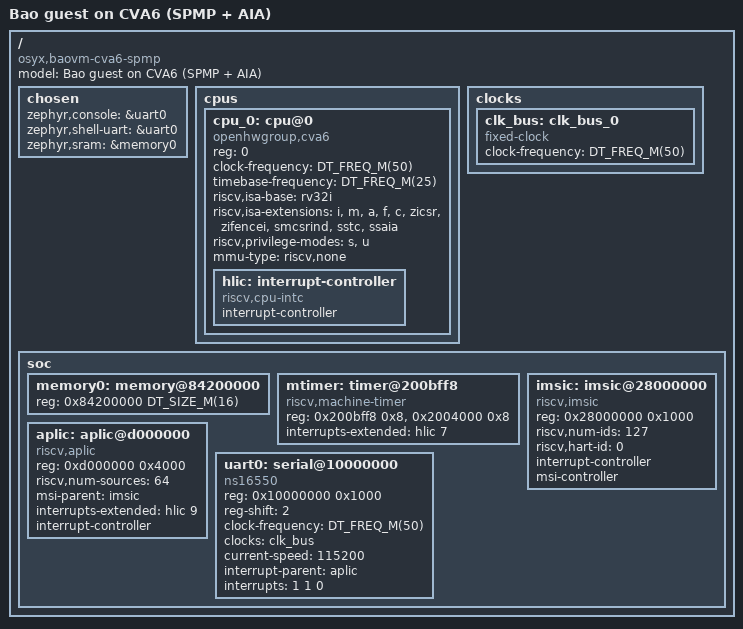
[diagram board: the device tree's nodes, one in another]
/*
 * SPDX-License-Identifier: Apache-2.0
 *
 * Bao guest on a CVA6-based MCU-class platform with SPMP and AIA.
 *
 * Addresses and IRQ numbers below match the cva6-spmp-guide Bao guest
 * configuration (cva6/bao_configs/cva6-spmp-dual-bm.c):
 *
 *   - VM memory region: 0x84200000, 16 MiB;
 *   - UART (NS16550): 0x10000000, 4 KiB, APLIC source 1;
 *   - AIA: APLIC at 0xd000000, IMSIC at 0x28000000;
 *   - IPC shared memory: 0x8A000000, 16 KiB, APLIC source 3
 *     (declared in the app.overlay, not here).
 */
/dts-v1/;

#include <freq.h>
#include <mem.h>

/ {
	model = "Bao guest on CVA6 (SPMP + AIA)";
	compatible = "osyx,baovm-cva6-spmp";

	#address-cells = <1>;
	#size-cells = <1>;

	chosen {
		zephyr,console = &uart0;
		zephyr,shell-uart = &uart0;
		zephyr,sram = &memory0;
	};

	cpus {
		#address-cells = <1>;
		#size-cells = <0>;

		cpu_0: cpu@0 {
			device_type = "cpu";
			compatible = "openhwgroup,cva6", "riscv";
			reg = <0>;
			clock-frequency = <DT_FREQ_M(50)>;
			timebase-frequency = <DT_FREQ_M(25)>;
			riscv,isa-base = "rv32i";
			riscv,isa-extensions = "i", "m", "a", "f", "c",
					       "zicsr", "zifencei",
					       "smcsrind", "sstc", "ssaia";
			riscv,privilege-modes = "s", "u";
			mmu-type = "riscv,none";
			status = "okay";

			hlic: interrupt-controller {
				#interrupt-cells = <1>;
				interrupt-controller;
				compatible = "riscv,cpu-intc";
				status = "okay";
			};
		};
	};

	clocks {
		clk_bus: clk_bus_0 {
			#clock-cells = <0>;
			compatible = "fixed-clock";
			clock-frequency = <DT_FREQ_M(50)>;
		};
	};

	soc {
		#address-cells = <1>;
		#size-cells = <1>;
		ranges;

		/* Memory slice assigned to this guest by Bao. */
		memory0: memory@84200000 {
			device_type = "memory";
			reg = <0x84200000 DT_SIZE_M(16)>;
		};

		/* Machine timer. With Sstc, S-mode can program the deadline via
		 * stimecmp directly; otherwise Zephyr falls back to an SBI
		 * ecall served by the supervisor above (Bao). */
		mtimer: timer@200bff8 {
			compatible = "riscv,machine-timer";
			reg = <0x200bff8 0x8>, <0x2004000 0x8>;
			reg-names = "mtime", "mtimecmp";
			interrupts-extended = <&hlic 7>;
		};

		/* AIA: per-hart S-mode IMSIC interrupt file mapped by Bao. The
		 * IMSIC is a leaf MSI-controller; in MSI mode it is the device
		 * that ultimately raises the S-mode external IRQ at the CPU,
		 * but Zephyr's irq-chain accounting treats the APLIC as the
		 * aggregator-level node (see below). */
		imsic: imsic@28000000 {
			compatible = "riscv,imsic";
			reg = <0x28000000 0x1000>;
			riscv,num-ids = <127>;
			riscv,hart-id = <0>;
			interrupt-controller;
			#interrupt-cells = <1>;
			msi-controller;
			status = "okay";
		};

		/* AIA: APLIC routing wired interrupts to the IMSIC above via
		 * MSI. interrupts-extended points at hlic 9 (S-mode external)
		 * so Zephyr's irq-chain level accounting puts the APLIC at
		 * aggregator level 2 (matching cv32a6's existing PLIC
		 * 2ND_LVL_ISR_TBL_OFFSET = 12). */
		aplic: aplic@d000000 {
			compatible = "riscv,aplic";
			reg = <0xd000000 0x4000>;
			riscv,num-sources = <64>;
			msi-parent = <&imsic>;
			interrupts-extended = <&hlic 9>;
			interrupt-controller;
			#interrupt-cells = <3>;
			status = "okay";
		};

		/* UART assigned to this guest by Bao. */
		uart0: serial@10000000 {
			compatible = "ns16550";
			reg = <0x10000000 0x1000>;
			reg-shift = <2>;
			clock-frequency = <DT_FREQ_M(50)>;
			clocks = <&clk_bus>;
			current-speed = <115200>;
			interrupt-parent = <&aplic>;
			interrupts = <1 1 0>;
			status = "okay";
		};
	};
};
